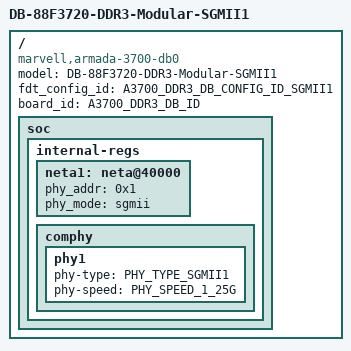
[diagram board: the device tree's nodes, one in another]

#include "armada-3700-ddr3-db.dts"

/* detail board setup:
 * Pcie Jumper slot	:	DB-88F3720-PCIe-mPCIe-Jumper
 * SGMII module slot	:	DB-88F3720-SerDes-Jumper
 * RGMII module slot	:	DB-88F3720-PHY module
 * eMMC slot		:	DB-88F3720-eMMC_NAND module
 * SDIO slot		:	DB-88F3720-SDcard module
 *
 * PHY0 (USB3/SGMII1)	:	SGMII1_Ethernet via PHY (1 Lane)
 * PHY1 (PCIe/SGMII0)	:	PCIe (WiFi via mini_PCIe module)
 * PHY2 (SATA)		:	SATA
 * RGMII		:	Ethernet via PHY (1 Lane)
 * USB2 Port 0		:	USB2 only
 * USB2 Port 1		:	USB2 Host
 * eMMC*		:	eMMC NAND
 * SDIO*		:	SD card
 * BOOT device*		:	SPI Flash
*/

/ {
	model = "DB-88F3720-DDR3-Modular-SGMII1";
	compatible = "marvell,armada-3700-db0", "marvell,armada-3700";
	fdt_config_id = <A3700_DDR3_DB_CONFIG_ID_SGMII1>;
	board_id = <A3700_DDR3_DB_ID>;

	soc {
		internal-regs {
			neta1: neta@40000 {
				status = "okay";
				phy_addr = <0x1>;
				phy_mode = "sgmii";
			};
			comphy {
				phy1 {
					phy-type = <PHY_TYPE_SGMII1>;
					phy-speed = <PHY_SPEED_1_25G>;
				};
			};
		};
	};
};
